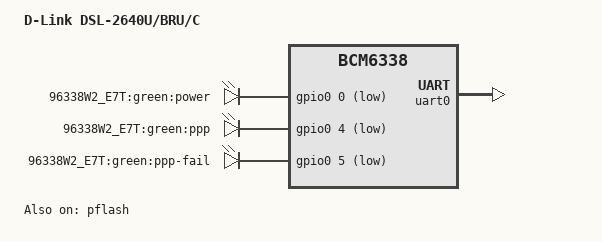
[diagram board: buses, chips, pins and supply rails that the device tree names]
/dts-v1/;

#include "bcm6338.dtsi"

#include <dt-bindings/input/input.h>

/ {
	model = "D-Link DSL-2640U/BRU/C";
	compatible = "d-link,dsl-2640u", "brcm,bcm6338";

	chosen {
		bootargs = "root=/dev/mtdblock2 rootfstype=squashfs,jffs2 noinitrd console=ttyS0,115200";
		stdout-path = "serial0:115200n8";
	};

	gpio-leds {
		compatible = "gpio-leds";

		green_power {
			label = "96338W2_E7T:green:power";
			gpios = <&gpio0 0 1>;
			default-state = "on";
		};

		green_stop {
			label = "96338W2_E7T:green:ppp";
			gpios = <&gpio0 4 1>;
		};

		green_adsl {
			label = "96338W2_E7T:green:ppp-fail";
			gpios = <&gpio0 5 1>;
		};
	};
};

&pflash {
	status = "ok";

	linux,part-probe = "bcm63xxpart";

	cfe@0 {
		label = "CFE";
		reg = <0x000000 0x010000>;
		read-only;
	};

	linux@10000 {
		label = "linux";
		reg = <0x010000 0x3e0000>;
	};

	nvram@3f0000 {
		label = "nvram";
		reg = <0x3f0000 0x010000>;
	};
};

&uart0 {
	status = "ok";
};
